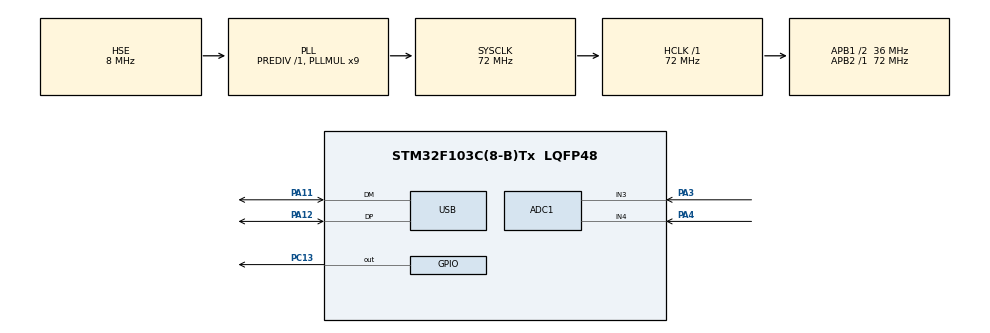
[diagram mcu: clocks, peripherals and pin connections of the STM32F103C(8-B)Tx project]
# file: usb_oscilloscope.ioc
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ADC1.Channel-0\#ChannelRegularConversion=ADC_CHANNEL_3
ADC1.Channel-1\#ChannelRegularConversion=ADC_CHANNEL_4
ADC1.ExternalTrigConv=ADC_EXTERNALTRIGCONV_T3_TRGO
ADC1.NbrOfConversion=2
ADC1.NbrOfConversionFlag=1
ADC1.Rank-0\#ChannelRegularConversion=1
ADC1.Rank-1\#ChannelRegularConversion=2
ADC1.SamplingTime-0\#ChannelRegularConversion=ADC_SAMPLETIME_28CYCLES_5
ADC1.SamplingTime-1\#ChannelRegularConversion=ADC_SAMPLETIME_28CYCLES_5
ADC1.master=1
Dma.ADC1.0.Direction=DMA_PERIPH_TO_MEMORY
Dma.ADC1.0.Instance=DMA1_Channel1
Dma.ADC1.0.MemDataAlignment=DMA_MDATAALIGN_HALFWORD
Dma.ADC1.0.MemInc=DMA_MINC_ENABLE
Dma.ADC1.0.Mode=DMA_CIRCULAR
Dma.ADC1.0.PeriphDataAlignment=DMA_PDATAALIGN_HALFWORD
Dma.ADC1.0.PeriphInc=DMA_PINC_DISABLE
Dma.ADC1.0.Priority=DMA_PRIORITY_LOW
Dma.Request0=ADC1
Mcu.Family=STM32F1
Mcu.Name=STM32F103C(8-B)Tx
Mcu.Package=LQFP48
NVIC.DMA1_Channel1_IRQn=true\:0\:0\:false\:false\:true\:false\:true
NVIC.PriorityGroup=NVIC_PRIORITYGROUP_4
NVIC.USB_LP_CAN1_RX0_IRQn=true\:0\:0\:false\:false\:true\:false\:true
PA11.Mode=Device
PA11.Signal=USB_DM
PA12.Mode=Device
PA12.Signal=USB_DP
PA3.Signal=ADCx_IN3
PA4.Signal=ADCx_IN4
PC13-TAMPER-RTC.GPIO_ModeDefaultOutputPP=GPIO_MODE_OUTPUT_OD
PC13-TAMPER-RTC.Signal=GPIO_Output
PD0-OSC_IN.Mode=HSE-External-Oscillator
PD0-OSC_IN.Signal=RCC_OSC_IN
PD1-OSC_OUT.Mode=HSE-External-Oscillator
PD1-OSC_OUT.Signal=RCC_OSC_OUT
ProjectManager.HeapSize=0x200
ProjectManager.StackSize=0x400
ProjectManager.TargetToolchain=Makefile
RCC.ADCPresc=RCC_ADCPCLK2_DIV6
RCC.AHBFreq_Value=72000000
RCC.APB1CLKDivider=RCC_HCLK_DIV2
RCC.APB1Freq_Value=36000000
RCC.APB1TimFreq_Value=72000000
RCC.APB2Freq_Value=72000000
RCC.APB2TimFreq_Value=72000000
RCC.HCLKFreq_Value=72000000
RCC.PLLMUL=RCC_PLL_MUL9
RCC.PLLSourceVirtual=RCC_PLLSOURCE_HSE
RCC.SYSCLKFreq_VALUE=72000000
RCC.SYSCLKSource=RCC_SYSCLKSOURCE_PLLCLK
RCC.USBFreq_Value=48000000
RCC.USBPrescaler=RCC_USBCLKSOURCE_PLL_DIV1_5
SH.ADCx_IN3.0=ADC1_IN3,IN3
SH.ADCx_IN4.0=ADC1_IN4,IN4
TIM3.AutoReloadPreload=TIM_AUTORELOAD_PRELOAD_ENABLE
TIM3.Channel-Output\ Compare1\ No\ Output=TIM_CHANNEL_1
TIM3.Period=2-1
TIM3.Prescaler=720-1
TIM3.TIM_MasterOutputTrigger=TIM_TRGO_UPDATE
USB_DEVICE.CLASS_NAME_FS=CDC
USB_DEVICE.VirtualMode=Cdc
USB_DEVICE.VirtualModeFS=Cdc_FS
VP_SYS_VS_ND.Mode=No_Debug
VP_TIM3_VS_ClockSourceINT.Mode=Internal
VP_TIM3_VS_no_output1.Mode=Output Compare1 No Output
VP_USB_DEVICE_VS_USB_DEVICE_CDC_FS.Mode=CDC_FS
board=custom

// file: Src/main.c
/* USER CODE BEGIN Header */
/**
  ******************************************************************************
  * @file           : main.c
  * @brief          : Main program body
  ******************************************************************************
  * @attention
  *
  * <h2><center>&copy; Copyright (c) 2020 STMicroelectronics.
  * All rights reserved.</center></h2>
  *
  * This software component is licensed by ST under Ultimate Liberty license
  * SLA0044, the "License"; You may not use this file except in compliance with
  * the License. You may obtain a copy of the License at:
  *                             www.st.com/SLA0044
  *
  ******************************************************************************
  */
/* USER CODE END Header */

#include "main.h"
#include "usb_device.h"

uint8_t CDC_Transmit_FS(uint8_t* Buf, uint16_t Len);

ADC_HandleTypeDef hadc1;
DMA_HandleTypeDef hdma_adc1;

TIM_HandleTypeDef htim3;

/* USER CODE BEGIN PV */
#define number_of_elements 5000
volatile uint16_t adc_buffer[number_of_elements] = {0};
/* USER CODE END PV */

void SystemClock_Config(void);
static void MX_GPIO_Init(void);
static void MX_DMA_Init(void);
static void MX_ADC1_Init(void);
static void MX_TIM3_Init(void);

int main(void)
{

  /* MCU Configuration--------------------------------------------------------*/

  /* Reset of all peripherals, Initializes the Flash interface and the Systick. */
  HAL_Init();

  /* Configure the system clock */
  SystemClock_Config();

  /* Initialize all configured peripherals */
  MX_GPIO_Init();
  MX_DMA_Init();
  MX_ADC1_Init();
  MX_USB_DEVICE_Init();
  MX_TIM3_Init();
  /* USER CODE BEGIN 2 */
  HAL_ADC_Start_DMA(&hadc1, (uint32_t*)&adc_buffer, number_of_elements);
  HAL_TIM_Base_Start(&htim3);
  /* USER CODE END 2 */

  /* Infinite loop */
  while (1)
  {

  }
}

void SystemClock_Config(void)
{
  RCC_OscInitTypeDef RCC_OscInitStruct = {0};
  RCC_ClkInitTypeDef RCC_ClkInitStruct = {0};
  RCC_PeriphCLKInitTypeDef PeriphClkInit = {0};

  /** Initializes the CPU, AHB and APB busses clocks
  */
  RCC_OscInitStruct.OscillatorType = RCC_OSCILLATORTYPE_HSE;
  RCC_OscInitStruct.HSEState = RCC_HSE_ON;
  RCC_OscInitStruct.HSEPredivValue = RCC_HSE_PREDIV_DIV1;
  RCC_OscInitStruct.HSIState = RCC_HSI_ON;
  RCC_OscInitStruct.PLL.PLLState = RCC_PLL_ON;
  RCC_OscInitStruct.PLL.PLLSource = RCC_PLLSOURCE_HSE;
  RCC_OscInitStruct.PLL.PLLMUL = RCC_PLL_MUL9;
  if (HAL_RCC_OscConfig(&RCC_OscInitStruct) != HAL_OK)
  {
    Error_Handler();
  }
  /** Initializes the CPU, AHB and APB busses clocks
  */
  RCC_ClkInitStruct.ClockType = RCC_CLOCKTYPE_HCLK|RCC_CLOCKTYPE_SYSCLK
                              |RCC_CLOCKTYPE_PCLK1|RCC_CLOCKTYPE_PCLK2;
  RCC_ClkInitStruct.SYSCLKSource = RCC_SYSCLKSOURCE_PLLCLK;
  RCC_ClkInitStruct.AHBCLKDivider = RCC_SYSCLK_DIV1;
  RCC_ClkInitStruct.APB1CLKDivider = RCC_HCLK_DIV2;
  RCC_ClkInitStruct.APB2CLKDivider = RCC_HCLK_DIV1;

  if (HAL_RCC_ClockConfig(&RCC_ClkInitStruct, FLASH_LATENCY_2) != HAL_OK)
  {
    Error_Handler();
  }
  PeriphClkInit.PeriphClockSelection = RCC_PERIPHCLK_ADC|RCC_PERIPHCLK_USB;
  PeriphClkInit.AdcClockSelection = RCC_ADCPCLK2_DIV6;
  PeriphClkInit.UsbClockSelection = RCC_USBCLKSOURCE_PLL_DIV1_5;
  if (HAL_RCCEx_PeriphCLKConfig(&PeriphClkInit) != HAL_OK)
  {
    Error_Handler();
  }
}

static void MX_ADC1_Init(void)
{

  ADC_ChannelConfTypeDef sConfig = {0};

  /** Common config
  */
  hadc1.Instance = ADC1;
  hadc1.Init.ScanConvMode = ADC_SCAN_ENABLE;
  hadc1.Init.ContinuousConvMode = DISABLE;
  hadc1.Init.DiscontinuousConvMode = DISABLE;
  hadc1.Init.ExternalTrigConv = ADC_EXTERNALTRIGCONV_T3_TRGO;
  hadc1.Init.DataAlign = ADC_DATAALIGN_RIGHT;
  hadc1.Init.NbrOfConversion = 2;
  if (HAL_ADC_Init(&hadc1) != HAL_OK)
  {
    Error_Handler();
  }
  /** Configure Regular Channel
  */
  sConfig.Channel = ADC_CHANNEL_3;
  sConfig.Rank = ADC_REGULAR_RANK_1;
  sConfig.SamplingTime = ADC_SAMPLETIME_28CYCLES_5;
  if (HAL_ADC_ConfigChannel(&hadc1, &sConfig) != HAL_OK)
  {
    Error_Handler();
  }
  /** Configure Regular Channel
  */
  sConfig.Channel = ADC_CHANNEL_4;
  sConfig.Rank = ADC_REGULAR_RANK_2;
  if (HAL_ADC_ConfigChannel(&hadc1, &sConfig) != HAL_OK)
  {
    Error_Handler();
  }

}

static void MX_TIM3_Init(void)
{

  TIM_ClockConfigTypeDef sClockSourceConfig = {0};
  TIM_MasterConfigTypeDef sMasterConfig = {0};
  TIM_OC_InitTypeDef sConfigOC = {0};

  htim3.Instance = TIM3;
  htim3.Init.Prescaler = 720-1;
  htim3.Init.CounterMode = TIM_COUNTERMODE_UP;
  htim3.Init.Period = 2-1;
  htim3.Init.ClockDivision = TIM_CLOCKDIVISION_DIV1;
  htim3.Init.AutoReloadPreload = TIM_AUTORELOAD_PRELOAD_ENABLE;
  if (HAL_TIM_Base_Init(&htim3) != HAL_OK)
  {
    Error_Handler();
  }
  sClockSourceConfig.ClockSource = TIM_CLOCKSOURCE_INTERNAL;
  if (HAL_TIM_ConfigClockSource(&htim3, &sClockSourceConfig) != HAL_OK)
  {
    Error_Handler();
  }
  if (HAL_TIM_OC_Init(&htim3) != HAL_OK)
  {
    Error_Handler();
  }
  sMasterConfig.MasterOutputTrigger = TIM_TRGO_UPDATE;
  sMasterConfig.MasterSlaveMode = TIM_MASTERSLAVEMODE_DISABLE;
  if (HAL_TIMEx_MasterConfigSynchronization(&htim3, &sMasterConfig) != HAL_OK)
  {
    Error_Handler();
  }
  sConfigOC.OCMode = TIM_OCMODE_TIMING;
  sConfigOC.Pulse = 0;
  sConfigOC.OCPolarity = TIM_OCPOLARITY_HIGH;
  sConfigOC.OCFastMode = TIM_OCFAST_DISABLE;
  if (HAL_TIM_OC_ConfigChannel(&htim3, &sConfigOC, TIM_CHANNEL_1) != HAL_OK)
  {
    Error_Handler();
  }

}

static void MX_DMA_Init(void)
{

  /* DMA controller clock enable */
  __HAL_RCC_DMA1_CLK_ENABLE();

  /* DMA interrupt init */
  /* DMA1_Channel1_IRQn interrupt configuration */
  HAL_NVIC_SetPriority(DMA1_Channel1_IRQn, 0, 0);
  HAL_NVIC_EnableIRQ(DMA1_Channel1_IRQn);

}

static void MX_GPIO_Init(void)
{
  GPIO_InitTypeDef GPIO_InitStruct = {0};

  /* GPIO Ports Clock Enable */
  __HAL_RCC_GPIOC_CLK_ENABLE();
  __HAL_RCC_GPIOD_CLK_ENABLE();
  __HAL_RCC_GPIOA_CLK_ENABLE();

  /*Configure GPIO pin Output Level */
  HAL_GPIO_WritePin(GPIOC, GPIO_PIN_13, GPIO_PIN_RESET);

  /*Configure GPIO pin : PC13 */
  GPIO_InitStruct.Pin = GPIO_PIN_13;
  GPIO_InitStruct.Mode = GPIO_MODE_OUTPUT_OD;
  GPIO_InitStruct.Pull = GPIO_NOPULL;
  GPIO_InitStruct.Speed = GPIO_SPEED_FREQ_LOW;
  HAL_GPIO_Init(GPIOC, &GPIO_InitStruct);

}

/* USER CODE BEGIN 4 */
//send to serial on half complete and complete
void HAL_ADC_ConvHalfCpltCallback(ADC_HandleTypeDef *hadc) {
	CDC_Transmit_FS((uint8_t *) adc_buffer, sizeof(adc_buffer)/2);
	HAL_GPIO_TogglePin(GPIOC, GPIO_PIN_13);
}
void HAL_ADC_ConvCpltCallback (ADC_HandleTypeDef *hadc) {
	CDC_Transmit_FS((uint8_t *) &adc_buffer[number_of_elements/2], sizeof(adc_buffer)/2);
	HAL_GPIO_TogglePin(GPIOC, GPIO_PIN_13);
}

void SYSTICK_1sec(void) {
	uint32_t cur_el = number_of_elements - (hadc1.DMA_Handle->Instance->CNDTR);
	adc_buffer[cur_el-1] = 0xFFFF;
}
/* USER CODE END 4 */

void Error_Handler(void)
{
}

/************************ (C) COPYRIGHT STMicroelectronics *****END OF FILE****/
